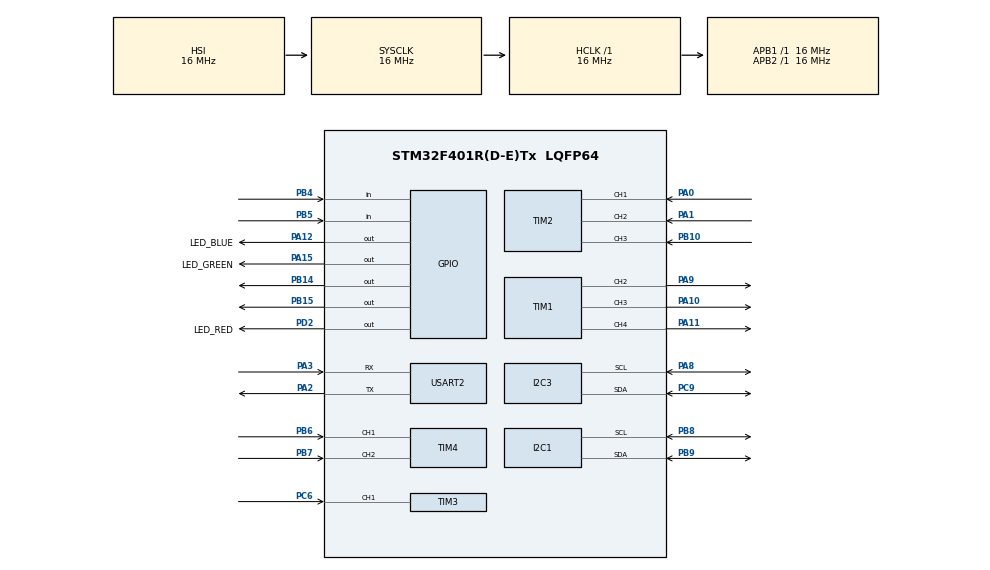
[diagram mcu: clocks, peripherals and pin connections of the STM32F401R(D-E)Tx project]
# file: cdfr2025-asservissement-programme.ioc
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Mcu.Family=STM32F4
Mcu.Name=STM32F401R(D-E)Tx
Mcu.Package=LQFP64
NVIC.PriorityGroup=NVIC_PRIORITYGROUP_4
PA0-WKUP.Signal=S_TIM2_CH1_ETR
PA1.Signal=S_TIM2_CH2
PA10.Signal=S_TIM1_CH3
PA11.Signal=S_TIM1_CH4
PA12.GPIO_Label=LED_BLUE
PA12.Signal=GPIO_Output
PA13.Mode=Trace_Asynchronous_SW
PA13.Signal=SYS_JTMS-SWDIO
PA14.Mode=Trace_Asynchronous_SW
PA14.Signal=SYS_JTCK-SWCLK
PA15.GPIO_Label=LED_GREEN
PA15.Signal=GPIO_Output
PA2.Mode=Asynchronous
PA2.Signal=USART2_TX
PA3.Mode=Asynchronous
PA3.Signal=USART2_RX
PA8.Mode=I2C
PA8.Signal=I2C3_SCL
PA9.Signal=S_TIM1_CH2
PB10.Signal=S_TIM2_CH3
PB14.Signal=GPIO_Output
PB15.Signal=GPIO_Output
PB3.Mode=Trace_Asynchronous_SW
PB3.Signal=SYS_JTDO-SWO
PB4.Signal=GPIO_Input
PB5.Signal=GPIO_Input
PB6.Signal=S_TIM4_CH1
PB7.Signal=S_TIM4_CH2
PB8.Mode=I2C
PB8.Signal=I2C1_SCL
PB9.Mode=I2C
PB9.Signal=I2C1_SDA
PC6.Signal=S_TIM3_CH1
PC9.Mode=I2C
PC9.Signal=I2C3_SDA
PD2.GPIO_Label=LED_RED
PD2.Signal=GPIO_Output
ProjectManager.HeapSize=0x200
ProjectManager.StackSize=0x400
ProjectManager.TargetToolchain=STM32CubeIDE
RCC.AHBFreq_Value=16000000
RCC.APB1Freq_Value=16000000
RCC.APB2Freq_Value=16000000
RCC.CortexFreq_Value=16000000
RCC.HSE_VALUE=25000000
RCC.HSI_VALUE=16000000
RCC.LSE_VALUE=32768
RCC.SYSCLKFreq_VALUE=16000000
RCC.VCOOutputFreq_Value=192000000
SH.S_TIM1_CH2.0=TIM1_CH2,PWM Generation2 CH2
SH.S_TIM1_CH3.0=TIM1_CH3,PWM Generation3 CH3
SH.S_TIM1_CH4.0=TIM1_CH4,PWM Generation4 CH4
SH.S_TIM2_CH1_ETR.0=TIM2_CH1,Encoder_Interface
SH.S_TIM2_CH2.0=TIM2_CH2,Encoder_Interface
SH.S_TIM2_CH3.0=TIM2_CH3,Input_Capture3_from_TI3
SH.S_TIM3_CH1.0=TIM3_CH1,Input_Capture1_from_TI1
SH.S_TIM4_CH1.0=TIM4_CH1,Encoder_Interface
SH.S_TIM4_CH2.0=TIM4_CH2,Encoder_Interface
TIM1.Channel-PWM\ Generation2\ CH2=TIM_CHANNEL_2
TIM1.Channel-PWM\ Generation3\ CH3=TIM_CHANNEL_3
TIM1.Channel-PWM\ Generation4\ CH4=TIM_CHANNEL_4
TIM2.Channel-Input_Capture3_from_TI3=TIM_CHANNEL_3
TIM3.Channel-Input_Capture1_from_TI1=TIM_CHANNEL_1
USART2.VirtualMode=VM_ASYNC
board=custom

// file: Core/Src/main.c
/* USER CODE BEGIN Header */
/**
  ******************************************************************************
  * @file           : main.c
  * @brief          : Main program body
  ******************************************************************************
  * @attention
  *
  * Copyright (c) 2024 STMicroelectronics.
  * All rights reserved.
  *
  * This software is licensed under terms that can be found in the LICENSE file
  * in the root directory of this software component.
  * If no LICENSE file comes with this software, it is provided AS-IS.
  *
  ******************************************************************************
  */
/* USER CODE END Header */
#include "main.h"

I2C_HandleTypeDef hi2c1;
I2C_HandleTypeDef hi2c3;

TIM_HandleTypeDef htim1;
TIM_HandleTypeDef htim2;
TIM_HandleTypeDef htim3;
TIM_HandleTypeDef htim4;

UART_HandleTypeDef huart2;

void SystemClock_Config(void);
static void MX_GPIO_Init(void);
static void MX_TIM2_Init(void);
static void MX_USART2_UART_Init(void);
static void MX_I2C1_Init(void);
static void MX_I2C3_Init(void);
static void MX_TIM1_Init(void);
static void MX_TIM3_Init(void);
static void MX_TIM4_Init(void);

int main(void)
{

  /* MCU Configuration--------------------------------------------------------*/

  /* Reset of all peripherals, Initializes the Flash interface and the Systick. */
  HAL_Init();

  /* Configure the system clock */
  SystemClock_Config();

  /* Initialize all configured peripherals */
  MX_GPIO_Init();
  MX_TIM2_Init();
  MX_USART2_UART_Init();
  MX_I2C1_Init();
  MX_I2C3_Init();
  MX_TIM1_Init();
  MX_TIM3_Init();
  MX_TIM4_Init();

  /* Infinite loop */
  /* USER CODE BEGIN WHILE */
  while (1)
  {
	  HAL_GPIO_TogglePin(LED_BLUE_GPIO_Port, LED_BLUE_Pin);
	  HAL_GPIO_TogglePin(LED_RED_GPIO_Port, LED_RED_Pin);
	  HAL_Delay(500);
	  HAL_GPIO_TogglePin(LED_BLUE_GPIO_Port, LED_BLUE_Pin);
	  HAL_Delay(500);
	/* USER CODE END WHILE */

  }
}

void SystemClock_Config(void)
{
  RCC_OscInitTypeDef RCC_OscInitStruct = {0};
  RCC_ClkInitTypeDef RCC_ClkInitStruct = {0};

  /** Configure the main internal regulator output voltage
  */
  __HAL_RCC_PWR_CLK_ENABLE();
  __HAL_PWR_VOLTAGESCALING_CONFIG(PWR_REGULATOR_VOLTAGE_SCALE2);

  /** Initializes the RCC Oscillators according to the specified parameters
  * in the RCC_OscInitTypeDef structure.
  */
  RCC_OscInitStruct.OscillatorType = RCC_OSCILLATORTYPE_HSI;
  RCC_OscInitStruct.HSIState = RCC_HSI_ON;
  RCC_OscInitStruct.HSICalibrationValue = RCC_HSICALIBRATION_DEFAULT;
  RCC_OscInitStruct.PLL.PLLState = RCC_PLL_NONE;
  if (HAL_RCC_OscConfig(&RCC_OscInitStruct) != HAL_OK)
  {
    Error_Handler();
  }

  /** Initializes the CPU, AHB and APB buses clocks
  */
  RCC_ClkInitStruct.ClockType = RCC_CLOCKTYPE_HCLK|RCC_CLOCKTYPE_SYSCLK
                              |RCC_CLOCKTYPE_PCLK1|RCC_CLOCKTYPE_PCLK2;
  RCC_ClkInitStruct.SYSCLKSource = RCC_SYSCLKSOURCE_HSI;
  RCC_ClkInitStruct.AHBCLKDivider = RCC_SYSCLK_DIV1;
  RCC_ClkInitStruct.APB1CLKDivider = RCC_HCLK_DIV1;
  RCC_ClkInitStruct.APB2CLKDivider = RCC_HCLK_DIV1;

  if (HAL_RCC_ClockConfig(&RCC_ClkInitStruct, FLASH_LATENCY_0) != HAL_OK)
  {
    Error_Handler();
  }
}

static void MX_I2C1_Init(void)
{

  hi2c1.Instance = I2C1;
  hi2c1.Init.ClockSpeed = 100000;
  hi2c1.Init.DutyCycle = I2C_DUTYCYCLE_2;
  hi2c1.Init.OwnAddress1 = 0;
  hi2c1.Init.AddressingMode = I2C_ADDRESSINGMODE_7BIT;
  hi2c1.Init.DualAddressMode = I2C_DUALADDRESS_DISABLE;
  hi2c1.Init.OwnAddress2 = 0;
  hi2c1.Init.GeneralCallMode = I2C_GENERALCALL_DISABLE;
  hi2c1.Init.NoStretchMode = I2C_NOSTRETCH_DISABLE;
  if (HAL_I2C_Init(&hi2c1) != HAL_OK)
  {
    Error_Handler();
  }

}

static void MX_I2C3_Init(void)
{

  hi2c3.Instance = I2C3;
  hi2c3.Init.ClockSpeed = 100000;
  hi2c3.Init.DutyCycle = I2C_DUTYCYCLE_2;
  hi2c3.Init.OwnAddress1 = 0;
  hi2c3.Init.AddressingMode = I2C_ADDRESSINGMODE_7BIT;
  hi2c3.Init.DualAddressMode = I2C_DUALADDRESS_DISABLE;
  hi2c3.Init.OwnAddress2 = 0;
  hi2c3.Init.GeneralCallMode = I2C_GENERALCALL_DISABLE;
  hi2c3.Init.NoStretchMode = I2C_NOSTRETCH_DISABLE;
  if (HAL_I2C_Init(&hi2c3) != HAL_OK)
  {
    Error_Handler();
  }

}

static void MX_TIM1_Init(void)
{

  TIM_MasterConfigTypeDef sMasterConfig = {0};
  TIM_OC_InitTypeDef sConfigOC = {0};
  TIM_BreakDeadTimeConfigTypeDef sBreakDeadTimeConfig = {0};

  htim1.Instance = TIM1;
  htim1.Init.Prescaler = 0;
  htim1.Init.CounterMode = TIM_COUNTERMODE_UP;
  htim1.Init.Period = 65535;
  htim1.Init.ClockDivision = TIM_CLOCKDIVISION_DIV1;
  htim1.Init.RepetitionCounter = 0;
  htim1.Init.AutoReloadPreload = TIM_AUTORELOAD_PRELOAD_DISABLE;
  if (HAL_TIM_PWM_Init(&htim1) != HAL_OK)
  {
    Error_Handler();
  }
  sMasterConfig.MasterOutputTrigger = TIM_TRGO_RESET;
  sMasterConfig.MasterSlaveMode = TIM_MASTERSLAVEMODE_DISABLE;
  if (HAL_TIMEx_MasterConfigSynchronization(&htim1, &sMasterConfig) != HAL_OK)
  {
    Error_Handler();
  }
  sConfigOC.OCMode = TIM_OCMODE_PWM1;
  sConfigOC.Pulse = 0;
  sConfigOC.OCPolarity = TIM_OCPOLARITY_HIGH;
  sConfigOC.OCNPolarity = TIM_OCNPOLARITY_HIGH;
  sConfigOC.OCFastMode = TIM_OCFAST_DISABLE;
  sConfigOC.OCIdleState = TIM_OCIDLESTATE_RESET;
  sConfigOC.OCNIdleState = TIM_OCNIDLESTATE_RESET;
  if (HAL_TIM_PWM_ConfigChannel(&htim1, &sConfigOC, TIM_CHANNEL_2) != HAL_OK)
  {
    Error_Handler();
  }
  if (HAL_TIM_PWM_ConfigChannel(&htim1, &sConfigOC, TIM_CHANNEL_3) != HAL_OK)
  {
    Error_Handler();
  }
  if (HAL_TIM_PWM_ConfigChannel(&htim1, &sConfigOC, TIM_CHANNEL_4) != HAL_OK)
  {
    Error_Handler();
  }
  sBreakDeadTimeConfig.OffStateRunMode = TIM_OSSR_DISABLE;
  sBreakDeadTimeConfig.OffStateIDLEMode = TIM_OSSI_DISABLE;
  sBreakDeadTimeConfig.LockLevel = TIM_LOCKLEVEL_OFF;
  sBreakDeadTimeConfig.DeadTime = 0;
  sBreakDeadTimeConfig.BreakState = TIM_BREAK_DISABLE;
  sBreakDeadTimeConfig.BreakPolarity = TIM_BREAKPOLARITY_HIGH;
  sBreakDeadTimeConfig.AutomaticOutput = TIM_AUTOMATICOUTPUT_DISABLE;
  if (HAL_TIMEx_ConfigBreakDeadTime(&htim1, &sBreakDeadTimeConfig) != HAL_OK)
  {
    Error_Handler();
  }
  HAL_TIM_MspPostInit(&htim1);

}

static void MX_TIM2_Init(void)
{

  TIM_Encoder_InitTypeDef sConfig = {0};
  TIM_MasterConfigTypeDef sMasterConfig = {0};
  TIM_IC_InitTypeDef sConfigIC = {0};

  htim2.Instance = TIM2;
  htim2.Init.Prescaler = 0;
  htim2.Init.CounterMode = TIM_COUNTERMODE_UP;
  htim2.Init.Period = 4294967295;
  htim2.Init.ClockDivision = TIM_CLOCKDIVISION_DIV1;
  htim2.Init.AutoReloadPreload = TIM_AUTORELOAD_PRELOAD_DISABLE;
  if (HAL_TIM_IC_Init(&htim2) != HAL_OK)
  {
    Error_Handler();
  }
  sConfig.EncoderMode = TIM_ENCODERMODE_TI1;
  sConfig.IC1Polarity = TIM_ICPOLARITY_RISING;
  sConfig.IC1Selection = TIM_ICSELECTION_DIRECTTI;
  sConfig.IC1Prescaler = TIM_ICPSC_DIV1;
  sConfig.IC1Filter = 0;
  sConfig.IC2Polarity = TIM_ICPOLARITY_RISING;
  sConfig.IC2Selection = TIM_ICSELECTION_DIRECTTI;
  sConfig.IC2Prescaler = TIM_ICPSC_DIV1;
  sConfig.IC2Filter = 0;
  if (HAL_TIM_Encoder_Init(&htim2, &sConfig) != HAL_OK)
  {
    Error_Handler();
  }
  sMasterConfig.MasterOutputTrigger = TIM_TRGO_RESET;
  sMasterConfig.MasterSlaveMode = TIM_MASTERSLAVEMODE_DISABLE;
  if (HAL_TIMEx_MasterConfigSynchronization(&htim2, &sMasterConfig) != HAL_OK)
  {
    Error_Handler();
  }
  sConfigIC.ICPolarity = TIM_INPUTCHANNELPOLARITY_RISING;
  sConfigIC.ICSelection = TIM_ICSELECTION_DIRECTTI;
  sConfigIC.ICPrescaler = TIM_ICPSC_DIV1;
  sConfigIC.ICFilter = 0;
  if (HAL_TIM_IC_ConfigChannel(&htim2, &sConfigIC, TIM_CHANNEL_3) != HAL_OK)
  {
    Error_Handler();
  }

}

static void MX_TIM3_Init(void)
{

  TIM_MasterConfigTypeDef sMasterConfig = {0};
  TIM_IC_InitTypeDef sConfigIC = {0};

  htim3.Instance = TIM3;
  htim3.Init.Prescaler = 0;
  htim3.Init.CounterMode = TIM_COUNTERMODE_UP;
  htim3.Init.Period = 65535;
  htim3.Init.ClockDivision = TIM_CLOCKDIVISION_DIV1;
  htim3.Init.AutoReloadPreload = TIM_AUTORELOAD_PRELOAD_DISABLE;
  if (HAL_TIM_IC_Init(&htim3) != HAL_OK)
  {
    Error_Handler();
  }
  sMasterConfig.MasterOutputTrigger = TIM_TRGO_RESET;
  sMasterConfig.MasterSlaveMode = TIM_MASTERSLAVEMODE_DISABLE;
  if (HAL_TIMEx_MasterConfigSynchronization(&htim3, &sMasterConfig) != HAL_OK)
  {
    Error_Handler();
  }
  sConfigIC.ICPolarity = TIM_INPUTCHANNELPOLARITY_RISING;
  sConfigIC.ICSelection = TIM_ICSELECTION_DIRECTTI;
  sConfigIC.ICPrescaler = TIM_ICPSC_DIV1;
  sConfigIC.ICFilter = 0;
  if (HAL_TIM_IC_ConfigChannel(&htim3, &sConfigIC, TIM_CHANNEL_1) != HAL_OK)
  {
    Error_Handler();
  }

}

static void MX_TIM4_Init(void)
{

  TIM_Encoder_InitTypeDef sConfig = {0};
  TIM_MasterConfigTypeDef sMasterConfig = {0};

  htim4.Instance = TIM4;
  htim4.Init.Prescaler = 0;
  htim4.Init.CounterMode = TIM_COUNTERMODE_UP;
  htim4.Init.Period = 65535;
  htim4.Init.ClockDivision = TIM_CLOCKDIVISION_DIV1;
  htim4.Init.AutoReloadPreload = TIM_AUTORELOAD_PRELOAD_DISABLE;
  sConfig.EncoderMode = TIM_ENCODERMODE_TI1;
  sConfig.IC1Polarity = TIM_ICPOLARITY_RISING;
  sConfig.IC1Selection = TIM_ICSELECTION_DIRECTTI;
  sConfig.IC1Prescaler = TIM_ICPSC_DIV1;
  sConfig.IC1Filter = 0;
  sConfig.IC2Polarity = TIM_ICPOLARITY_RISING;
  sConfig.IC2Selection = TIM_ICSELECTION_DIRECTTI;
  sConfig.IC2Prescaler = TIM_ICPSC_DIV1;
  sConfig.IC2Filter = 0;
  if (HAL_TIM_Encoder_Init(&htim4, &sConfig) != HAL_OK)
  {
    Error_Handler();
  }
  sMasterConfig.MasterOutputTrigger = TIM_TRGO_RESET;
  sMasterConfig.MasterSlaveMode = TIM_MASTERSLAVEMODE_DISABLE;
  if (HAL_TIMEx_MasterConfigSynchronization(&htim4, &sMasterConfig) != HAL_OK)
  {
    Error_Handler();
  }

}

static void MX_USART2_UART_Init(void)
{

  huart2.Instance = USART2;
  huart2.Init.BaudRate = 115200;
  huart2.Init.WordLength = UART_WORDLENGTH_8B;
  huart2.Init.StopBits = UART_STOPBITS_1;
  huart2.Init.Parity = UART_PARITY_NONE;
  huart2.Init.Mode = UART_MODE_TX_RX;
  huart2.Init.HwFlowCtl = UART_HWCONTROL_NONE;
  huart2.Init.OverSampling = UART_OVERSAMPLING_16;
  if (HAL_UART_Init(&huart2) != HAL_OK)
  {
    Error_Handler();
  }

}

static void MX_GPIO_Init(void)
{
  GPIO_InitTypeDef GPIO_InitStruct = {0};

  /* GPIO Ports Clock Enable */
  __HAL_RCC_GPIOA_CLK_ENABLE();
  __HAL_RCC_GPIOB_CLK_ENABLE();
  __HAL_RCC_GPIOC_CLK_ENABLE();
  __HAL_RCC_GPIOD_CLK_ENABLE();

  /*Configure GPIO pin Output Level */
  HAL_GPIO_WritePin(GPIOB, GPIO_PIN_14|GPIO_PIN_15, GPIO_PIN_RESET);

  /*Configure GPIO pin Output Level */
  HAL_GPIO_WritePin(GPIOA, LED_BLUE_Pin|LED_GREEN_Pin, GPIO_PIN_RESET);

  /*Configure GPIO pin Output Level */
  HAL_GPIO_WritePin(LED_RED_GPIO_Port, LED_RED_Pin, GPIO_PIN_RESET);

  /*Configure GPIO pins : PB14 PB15 */
  GPIO_InitStruct.Pin = GPIO_PIN_14|GPIO_PIN_15;
  GPIO_InitStruct.Mode = GPIO_MODE_OUTPUT_PP;
  GPIO_InitStruct.Pull = GPIO_NOPULL;
  GPIO_InitStruct.Speed = GPIO_SPEED_FREQ_LOW;
  HAL_GPIO_Init(GPIOB, &GPIO_InitStruct);

  /*Configure GPIO pins : LED_BLUE_Pin LED_GREEN_Pin */
  GPIO_InitStruct.Pin = LED_BLUE_Pin|LED_GREEN_Pin;
  GPIO_InitStruct.Mode = GPIO_MODE_OUTPUT_PP;
  GPIO_InitStruct.Pull = GPIO_NOPULL;
  GPIO_InitStruct.Speed = GPIO_SPEED_FREQ_LOW;
  HAL_GPIO_Init(GPIOA, &GPIO_InitStruct);

  /*Configure GPIO pin : LED_RED_Pin */
  GPIO_InitStruct.Pin = LED_RED_Pin;
  GPIO_InitStruct.Mode = GPIO_MODE_OUTPUT_PP;
  GPIO_InitStruct.Pull = GPIO_NOPULL;
  GPIO_InitStruct.Speed = GPIO_SPEED_FREQ_LOW;
  HAL_GPIO_Init(LED_RED_GPIO_Port, &GPIO_InitStruct);

  /*Configure GPIO pins : PB4 PB5 */
  GPIO_InitStruct.Pin = GPIO_PIN_4|GPIO_PIN_5;
  GPIO_InitStruct.Mode = GPIO_MODE_INPUT;
  GPIO_InitStruct.Pull = GPIO_NOPULL;
  HAL_GPIO_Init(GPIOB, &GPIO_InitStruct);

}

void Error_Handler(void)
{
  __disable_irq();
  while (1)
  {
  }
}
